# CM_DEVICE register map
Vendor: Texas Instruments
Peripheral module from a debugger description file (folder am335x).
Registers are 32-bit, access per field, no defined reset value unless marked. A register's access mark holds for its fields unless they carry their own. Offsets are as the file gives them; lines under a group give offsets from that group; [hi:lo] are bit positions; {n}, {i} and the like mark numbered series; 'fields as' and 'values as' point back to an identical list; <NAME> marks a mode.

## CM_DEVICE
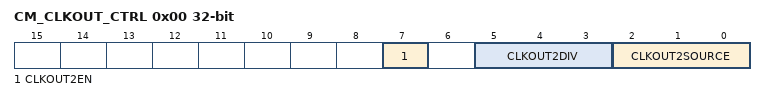
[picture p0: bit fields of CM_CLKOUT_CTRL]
0x00 CM_CLKOUT_CTRL — This register provides the control over CLKOUT2 output
  [7] CLKOUT2EN rw — This bit controls the external clock activity
    0=DIS (SYS_CLKOUT2 is disabled); 1=EN (SYS_CLKOUT2 is enabled)
  [5:3] CLKOUT2DIV rw — THis field controls the external clock divison factor
    {v}=DIV{v+1} (SYS_CLKOUT2/{v+1}) (v=0..7)
  [2:0] CLKOUT2SOURCE rw — This field selects the external output clock source
    0=SEL0 (Select 32KHz Oscillator O/P); 1=SEL1 (Select L3 Clock); 2=SEL2 (Select DDR PHY Clock); 3=SEL4 (Select 192Mhz clock from PER PLL); 4=SEL5 (Select LCD Pixel Clock)
